AUTOSAR XML (schema 4-0-3)
package /ComponentTypes
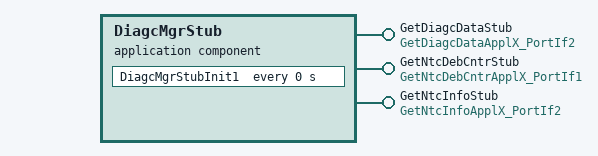
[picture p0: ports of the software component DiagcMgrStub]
  application sw component type DiagcMgrStub
    provide port GetDiagcDataStub: server-com-spec{operation=Oper, queue-length=1}, provided-interface=GetDiagcDataApplX_PortIf2
    provide port GetNtcDebCntrStub: server-com-spec{operation=Oper, queue-length=1}, provided-interface=GetNtcDebCntrApplX_PortIf1
    provide port GetNtcInfoStub: server-com-spec{operation=Oper, queue-length=1}, provided-interface=GetNtcInfoApplX_PortIf2
    behavior DiagcMgrStub_InternalBehavior
      timing event DiagcMgrStub_InitEvent: start-on-event=DiagcMgrStubInit1, period=0
      operation invoked event OIT_GetDiagcDataStub_Oper_GetDiagcDataStub_Oper: start-on-event=GetDiagcDataStub_Oper, operation=GetDiagcDataStub.Oper
      operation invoked event OIT_GetNtcDebCntrStub_Oper_GetNtcDebCntrStub_Oper: start-on-event=GetNtcDebCntrStub_Oper, operation=GetNtcDebCntrStub.Oper
      operation invoked event OIT_GetNtcInfoStub_Oper_GetNtcInfoStub_Oper: start-on-event=GetNtcInfoStub_Oper, operation=GetNtcInfoStub.Oper
      4 x runnable:
        DiagcMgrStubInit1
        GetDiagcDataStub_Oper: can-be-invoked-concurrently=true
        GetNtcDebCntrStub_Oper: can-be-invoked-concurrently=true
        GetNtcInfoStub_Oper: can-be-invoked-concurrently=true
  swc implementation DiagcMgrStub_Implementation: behavior=DiagcMgrStub_InternalBehavior
    code-descriptors:
      code Default: artifact-descriptors=autosar-engineering-object={short-label=Default, category=SWSRC}
